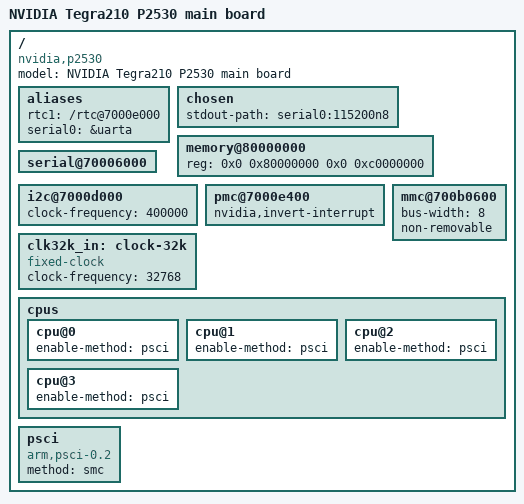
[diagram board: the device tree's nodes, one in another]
// SPDX-License-Identifier: GPL-2.0
#include "tegra210.dtsi"

/ {
	model = "NVIDIA Tegra210 P2530 main board";
	compatible = "nvidia,p2530", "nvidia,tegra210";

	aliases {
		rtc1 = "/rtc@7000e000";
		serial0 = &uarta;
	};

	chosen {
		stdout-path = "serial0:115200n8";
	};

	memory@80000000 {
		device_type = "memory";
		reg = <0x0 0x80000000 0x0 0xc0000000>;
	};

	/* debug port */
	serial@70006000 {
		/delete-property/ dmas;
		/delete-property/ dma-names;
		status = "okay";
	};

	i2c@7000d000 {
		status = "okay";
		clock-frequency = <400000>;
	};

	pmc@7000e400 {
		nvidia,invert-interrupt;
	};

	/* eMMC */
	mmc@700b0600 {
		status = "okay";
		bus-width = <8>;
		non-removable;
	};

	clk32k_in: clock-32k {
		compatible = "fixed-clock";
		clock-frequency = <32768>;
		#clock-cells = <0>;
	};

	cpus {
		cpu@0 {
			enable-method = "psci";
		};

		cpu@1 {
			enable-method = "psci";
		};

		cpu@2 {
			enable-method = "psci";
		};

		cpu@3 {
			enable-method = "psci";
		};
	};

	psci {
		compatible = "arm,psci-0.2";
		method = "smc";
	};
};
